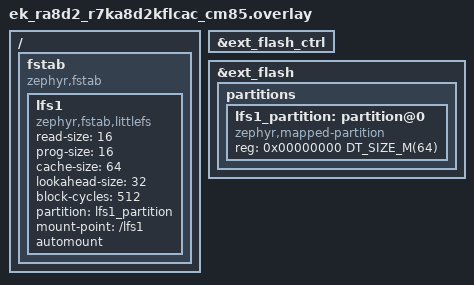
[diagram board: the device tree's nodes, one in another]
/*
 * Copyright (c) 2026 Renesas Electronics Corporation
 *
 * SPDX-License-Identifier: Apache-2.0
 */

&ext_flash_ctrl {
	status = "okay";
};

&ext_flash {
	status = "okay";

	partitions {
		#address-cells = <1>;
		#size-cells = <1>;
		ranges;

		/* 64MiB external storage partition */
		lfs1_partition: partition@0 {
			compatible = "zephyr,mapped-partition";
			reg = <0x00000000 DT_SIZE_M(64)>;
		};
	};
};

/ {
	fstab {
		compatible = "zephyr,fstab";

		lfs1: lfs1 {
			compatible = "zephyr,fstab,littlefs";
			read-size = <16>;
			prog-size = <16>;
			cache-size = <64>;
			lookahead-size = <32>;
			block-cycles = <512>;
			partition = <&lfs1_partition>;
			mount-point = "/lfs1";
			automount;
		};
	};
};
